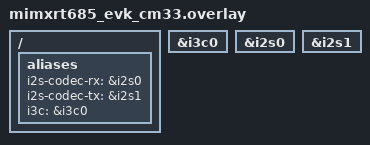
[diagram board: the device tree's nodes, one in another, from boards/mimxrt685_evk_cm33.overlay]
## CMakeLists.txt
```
# SPDX-License-Identifier: Apache-2.0

cmake_minimum_required(VERSION 3.20.0)

find_package(Zephyr REQUIRED HINTS $ENV{ZEPHYR_BASE})
project(i2s_codec)

FILE(GLOB app_sources src/*.c)
target_sources(app PRIVATE src/main.c src/wm8904.c)
```

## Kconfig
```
# Copyright (c) 2024 NXP
# SPDX-License-Identifier: Apache-2.0

source "Kconfig.zephyr"

config I2S_INIT_BUFFERS
	int "number of i2s transfer buffer"
	default 2
	help
	  i2s init buffers used in transfer

config SAMPLE_FREQ
	int "sample rate"
	default 48000
	help
	  fample rate
```

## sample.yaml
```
sample:
  name: codec sample
tests:
  sample.drivers.i2s.codec:
    tags: i2s
    filter: dt_alias_exists("i2s_codec")
    platform_allow:
      - mimxrt685_evk_cm33
    harness: console
    harness_config:
      type: one_line
      regex:
        - "start streams"
```

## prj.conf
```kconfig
CONFIG_I2S=y
#CONFIG_LOG=y
CONFIG_AUDIO=y
```

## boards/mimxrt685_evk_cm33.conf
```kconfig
#
# Copyright (c) 2023, NXP
#
# SPDX-License-Identifier: Apache-2.0
#

CONFIG_DMA=y
CONFIG_I2S_MCUX_FLEXCOMM=y
CONFIG_I3C=y
CONFIG_HEAP_MEM_POOL_SIZE=81920
CONFIG_AUDIO=y
CONFIG_AUDIO_CODEC=y
CONFIG_AUDIO_CODEC_WM8904=y
CONFIG_I2S_INIT_BUFFERS=4
CONFIG_SAMPLE_FREQ=16000
```

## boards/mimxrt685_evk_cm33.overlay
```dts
/ {
        aliases {
                i2s-codec-rx = &i2s0;
                i2s-codec-tx = &i2s1;
                i3c=&i3c0;
        };

};

&i3c0 {
    status = "okay";
};

&i2s0 {
    status = "okay";
};

&i2s1 {
    status = "okay";
};
```

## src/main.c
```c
/*
 * Copyright (c) 2024 NXP
 *
 * SPDX-License-Identifier: Apache-2.0
 */

#include <zephyr/kernel.h>
#include <zephyr/sys/printk.h>
#include <zephyr/drivers/i2s.h>
#include <zephyr/drivers/i3c.h>
#include <zephyr/drivers/gpio.h>
#include <zephyr/audio/codec.h>
#include <string.h>
#include "wm8904.h"


#define SAMPLE_FREQUENCY    48000
#define SAMPLE_BIT_WIDTH    (16U)
#define BYTES_PER_SAMPLE    sizeof(int16_t)
#define NUMBER_OF_CHANNELS  2U
/* Such block length provides an echo with the delay of 100 ms. */
#define SAMPLES_PER_BLOCK   ((SAMPLE_FREQUENCY / 10) * NUMBER_OF_CHANNELS)
#define INITIAL_BLOCKS      2
#define TIMEOUT             (2000U)

#define BLOCK_SIZE  (BYTES_PER_SAMPLE * SAMPLES_PER_BLOCK)
#define BLOCK_COUNT (INITIAL_BLOCKS + 2)
K_MEM_SLAB_DEFINE_STATIC(mem_slab, BLOCK_SIZE, BLOCK_COUNT, 4);

void read_buf(int16_t *rx_block) {
	int sample_no = BLOCK_SIZE;

	for (int i = 0; i < sample_no; i++) {
		printk("Data n°%d: %d\n", i, rx_block[i]);
	}
}

static bool prepare_transfer(const struct device *i2s_dev_rx,
			     const struct device *i2s_dev_tx)
{
	int ret;

	for (int i = 0; i < INITIAL_BLOCKS; ++i) {
		void *mem_block;

		ret = k_mem_slab_alloc(&mem_slab, &mem_block, K_NO_WAIT);
		if (ret < 0) {
			printk("Failed to allocate TX block %d: %d\n", i, ret);
			return false;
		}

		memset(mem_block, 0, BLOCK_SIZE);

		ret = i2s_write(i2s_dev_tx, mem_block, BLOCK_SIZE);
		if (ret < 0) {
			printk("Failed to write block for trigger\n");
			return false;
		}
	}

	return true;
}

int config_i2s(const struct device *dev_i2s_tx, const struct device *dev_i2s_rx)
{
	int ret;
	struct i2s_config i2s_cfg;

	i2s_cfg.word_size = 16U;
	i2s_cfg.channels = NUMBER_OF_CHANNELS;
	i2s_cfg.format = I2S_FMT_DATA_FORMAT_I2S;
	i2s_cfg.frame_clk_freq = SAMPLE_FREQUENCY;
	i2s_cfg.block_size = BLOCK_SIZE;
	i2s_cfg.options = I2S_OPT_FRAME_CLK_MASTER | I2S_OPT_BIT_CLK_MASTER;
	i2s_cfg.mem_slab = &mem_slab;
	i2s_cfg.timeout = TIMEOUT;

	ret = i2s_configure(dev_i2s_tx, I2S_DIR_TX, &i2s_cfg);
	if (ret < 0) {
		printk("Failed to configure I2S stream\n");
		return ret;
	}

	ret = i2s_configure(dev_i2s_rx, I2S_DIR_RX, &i2s_cfg);
	if (ret < 0) {
		printk("Failed to configure I2S stream\n");
		return ret;
	}
	return 0;
}

int main(void)
{
	const struct device *const dev_i2s_rx = DEVICE_DT_GET(DT_NODELABEL(i2s0));
	const struct device *const dev_i2s_tx = DEVICE_DT_GET(DT_NODELABEL(i2s1));
	const struct device *const codec_dev = DEVICE_DT_GET(DT_NODELABEL(audio_codec));
	struct audio_codec_cfg audio_cfg;

	printk("I2S sample\n");

	if (!device_is_ready(dev_i2s_rx)) {
		printk("%s is not ready\n", dev_i2s_rx->name);
		return 0;
	} else {
		printk("%s is ready\n", dev_i2s_rx->name);
	}

	printk("I2S Init.\n");

	audio_cfg.dai_type = AUDIO_DAI_TYPE_I2S;
	audio_cfg.dai_cfg.i2s.word_size = SAMPLE_BIT_WIDTH;
	audio_cfg.dai_cfg.i2s.channels =  2;
	audio_cfg.dai_cfg.i2s.format = I2S_FMT_DATA_FORMAT_I2S;
	audio_cfg.dai_cfg.i2s.options = I2S_OPT_FRAME_CLK_SLAVE;
	audio_cfg.dai_cfg.i2s.frame_clk_freq = SAMPLE_FREQUENCY;
	audio_cfg.dai_cfg.i2s.mem_slab = &mem_slab;
	audio_cfg.dai_cfg.i2s.block_size = BLOCK_SIZE;
	audio_codec_configure(codec_dev, &audio_cfg);
	k_msleep(1000);

	config_i2s(dev_i2s_tx, dev_i2s_rx);

	printk("I2S ready\n");

	int ret;

	while (1) {
		int error = 0;
		/* Start reception */

		if (!prepare_transfer(dev_i2s_rx, dev_i2s_tx)) {
			return 0;
		}

		ret = i2s_trigger(dev_i2s_rx, I2S_DIR_RX, I2S_TRIGGER_START);
		if (ret < 0) {
			printf("Problème: could not trigger start I2S rx\n");
			return ret;
		}

		ret = i2s_trigger(dev_i2s_tx, I2S_DIR_TX, I2S_TRIGGER_START);
		if (ret < 0) {
			printf("Problème: could not trigger start I2S rx\n");
			return ret;
		}

		while (1) {
			void *rx_block;
			uint32_t rx_size;

			ret = i2s_read(dev_i2s_rx, &rx_block, &rx_size);
			if (ret < 0) {
				error++;
				printk("Problème (%i): réception buffer (%i)\n", ret, error);
				break;
			}

			/* read_buf((uint16_t *)rx_block); */

			ret = i2s_write(dev_i2s_tx, rx_block, rx_size);
			if (ret < 0) {
				printk("Failed to write data: %d\n", ret);
				break;
			}
		}

		/* Stop reception */
		ret = i2s_trigger(dev_i2s_rx, I2S_DIR_RX, I2S_TRIGGER_DROP);
		if (ret < 0) {
			printf("Problème: could not trigger stop I2S rx\n");
			return ret;
		}

		ret = i2s_trigger(dev_i2s_tx, I2S_DIR_TX, I2S_TRIGGER_DROP);
		if (ret < 0) {
			printf("Problème: could not trigger stop I2S rx\n");
			return ret;
		}
	}
	return 0;
}
```

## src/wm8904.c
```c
/*
 * Copyright (c) 2021 Nordic Semiconductor ASA
 * SPDX-License-Identifier: Apache-2.0
 */

#include "wm8904.h"

int wm8904_reg_write(uint8_t reg_addr, uint16_t value)
{
	uint8_t buf[3];

	buf[0] = reg_addr;
	buf[1] = value >> 8;   // Octet de poids fort de la valeur
	buf[2] = value & 0xFF; // Octet de poids faible de la valeur

	struct i2c_msg msgs[1];
	msgs[0].buf = (uint8_t *)buf;
	msgs[0].len = ARRAY_SIZE(buf);
	msgs[0].flags = I2C_MSG_WRITE | I2C_MSG_STOP;

	if (i2c_transfer(i2c_dev, msgs, ARRAY_SIZE(msgs), wm8904_I2C_ADDR) != 0) {
		printk("Erreur lors de l'écriture du registre WM8904.\n");
		return -1;
	}

	return 0;
}

int wm8904_reg_read(const void *write_buf, size_t num_write, void *read_buf, size_t num_read)
{
	struct i2c_msg msg[2];

	msg[0].buf = (uint8_t *)write_buf;
	msg[0].len = num_write;
	msg[0].flags = I2C_MSG_WRITE;

	msg[1].buf = (uint8_t *)read_buf;
	msg[1].len = num_read;
	msg[1].flags = I2C_MSG_RESTART | I2C_MSG_READ | I2C_MSG_STOP;

	if (i2c_transfer(i2c_dev, msg, ARRAY_SIZE(msg), wm8904_I2C_ADDR) != 0) {
		printk("Erreur i2c write read\n");
		return -1;
	}
	return 0;
}

int wm8904_WaitOnWriteSequencer()
{
    int result;
    uint8_t value[2];
	uint8_t reg[1] = {WM8904_WRITE_SEQUENCER_4};
	uint16_t reg_val;

	result = wm8904_reg_read(reg, ARRAY_SIZE(reg), &value, ARRAY_SIZE(value));
	reg_val = (value[0] * 256) | value[1];

    while ((reg_val & 0x0001) != 0x0000){
		k_msleep(10);
        result = wm8904_reg_read(reg, ARRAY_SIZE(reg), &value, ARRAY_SIZE(value));
		reg_val = (value[0] * 256) | value[1];
    }

    return result;
}

int wm8904_reg_modify(uint8_t registre, uint16_t mask, uint16_t value){
	int ret;
	uint8_t reg[1] = {registre};
	uint8_t regVal[2];
	uint16_t val;

	ret=wm8904_reg_read(reg, ARRAY_SIZE(reg), &regVal, ARRAY_SIZE(regVal));
	if(ret<0){
		return ret;
	}

	val = (regVal[0] * 256) | regVal[1];
	val &= (uint16_t)~mask;
	val |= value;

	return wm8904_reg_write(reg[0], val);
}

int wm8904_read_allregisters(){
	uint8_t allRegisters[] = {
    0x00, 0x04, 0x05, 0x06, 0x07, 0x0A, 0x0C, 0x0E, 0x0F, 0x12, 0x14, 0x15, 0x16, 0x18, 0x19, 0x1A, 0x1B,
    0x1E, 0x1F, 0x20, 0x21, 0x24, 0x25, 0x26, 0x27, 0x28, 0x29, 0x2A, 0x2B, 0x2C, 0x2D, 0x2E, 0x2F, 0x39,
    0x3A, 0x3B, 0x3C, 0x3D, 0x43, 0x44, 0x45, 0x47, 0x48, 0x49, 0x4A, 0x4B, 0x4C, 0x4D, 0x5A, 0x5E, 0x62,
    0x68, 0x6C, 0x6D, 0x6E, 0x6F, 0x70, 0x74, 0x75, 0x76, 0x77, 0x78, 0x79, 0x7A, 0x7B, 0x7C, 0x7E, 0x7F,
    0x80, 0x81, 0x82, 0x86, 0x87, 0x88, 0x89, 0x8A, 0x8B, 0x8C, 0x8D, 0x8E, 0x8F, 0x90, 0x91, 0x92, 0x93,
    0x94, 0x95, 0x96, 0x97, 0x98, 0x99, 0x9A, 0x9B, 0x9C, 0x9D, 0xC6, 0xF7, 0xF8};

	int ret;

	for(int i = 0; i<ARRAY_SIZE(allRegisters); i++){
		uint8_t reg[1] = {allRegisters[i]};
		uint8_t test[2];
		uint16_t united_test;

		ret = wm8904_reg_read(reg, ARRAY_SIZE(reg), &test, ARRAY_SIZE(test));
		if (ret < 0) {
			printk("WM8904 is not ready\n");
			return ret;
		}
		united_test = (test[0] * 256) | test[1];
		printk("registre 0x%x --> 0x%x\n", allRegisters[i], united_test);
	}

	return 0;
}
```
